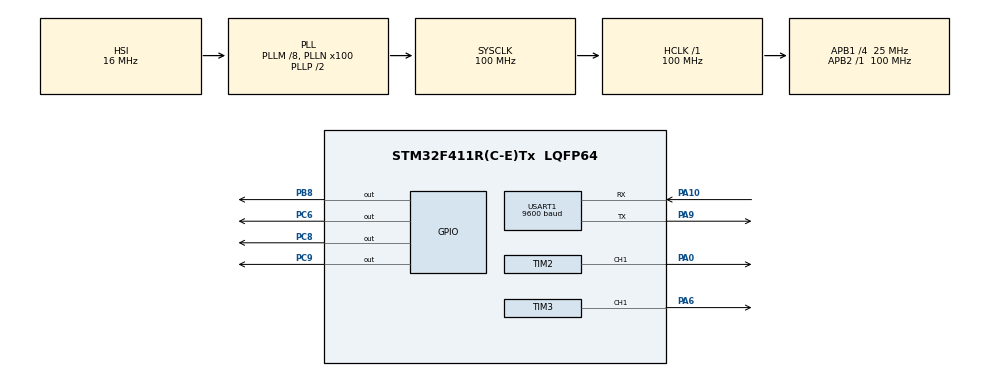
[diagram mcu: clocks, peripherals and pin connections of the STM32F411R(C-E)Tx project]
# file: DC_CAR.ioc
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Mcu.Family=STM32F4
Mcu.Name=STM32F411R(C-E)Tx
Mcu.Package=LQFP64
NVIC.PriorityGroup=NVIC_PRIORITYGROUP_4
NVIC.USART1_IRQn=true\:0\:0\:false\:false\:true\:true\:true\:true
PA0-WKUP.Signal=S_TIM2_CH1_ETR
PA10.Mode=Asynchronous
PA10.Signal=USART1_RX
PA13.Mode=Serial_Wire
PA13.Signal=SYS_JTMS-SWDIO
PA14.Mode=Serial_Wire
PA14.Signal=SYS_JTCK-SWCLK
PA6.Signal=S_TIM3_CH1
PA9.Mode=Asynchronous
PA9.Signal=USART1_TX
PB8.Signal=GPIO_Output
PC6.Signal=GPIO_Output
PC8.Signal=GPIO_Output
PC9.Signal=GPIO_Output
PH0\ -\ OSC_IN.Mode=HSE-External-Clock-Source
PH0\ -\ OSC_IN.Signal=RCC_OSC_IN
PH1\ -\ OSC_OUT.Mode=HSE-External-Clock-Source
PH1\ -\ OSC_OUT.Signal=RCC_OSC_OUT
ProjectManager.HeapSize=0x200
ProjectManager.StackSize=0x400
ProjectManager.TargetToolchain=STM32CubeIDE
RCC.48MHZClocksFreq_Value=50000000
RCC.AHBFreq_Value=100000000
RCC.APB1CLKDivider=RCC_HCLK_DIV4
RCC.APB1Freq_Value=25000000
RCC.APB1TimFreq_Value=50000000
RCC.APB2Freq_Value=100000000
RCC.APB2TimFreq_Value=100000000
RCC.CortexFreq_Value=100000000
RCC.HCLKFreq_Value=100000000
RCC.HSE_VALUE=8000000
RCC.HSI_VALUE=16000000
RCC.LSE_VALUE=32768
RCC.PLLM=8
RCC.PLLN=100
RCC.RCC_RTC_Clock_Source=RCC_RTCCLKSOURCE_LSI
RCC.RCC_RTC_Clock_SourceVirtual=RCC_RTCCLKSOURCE_LSI
RCC.SYSCLKFreq_VALUE=100000000
RCC.SYSCLKSource=RCC_SYSCLKSOURCE_PLLCLK
RCC.VCOOutputFreq_Value=200000000
SH.S_TIM2_CH1_ETR.0=TIM2_CH1,PWM Generation1 CH1
SH.S_TIM3_CH1.0=TIM3_CH1,PWM Generation1 CH1
TIM2.Channel-PWM\ Generation1\ CH1=TIM_CHANNEL_1
TIM3.Channel-PWM\ Generation1\ CH1=TIM_CHANNEL_1
TIM3.Period=2000-1
TIM3.Prescaler=1000-1
TIM3.Pulse-PWM\ Generation1\ CH1=300
USART1.BaudRate=9600
USART1.VirtualMode=VM_ASYNC
VP_TIM2_VS_ClockSourceINT.Mode=Internal
VP_TIM3_VS_ClockSourceINT.Mode=Internal
board=custom

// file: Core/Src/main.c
/* USER CODE BEGIN Header */
/**
  ******************************************************************************
  * @file           : main.c
  * @brief          : Main program body
  ******************************************************************************
  * @attention
  *
  * Copyright (c) 2026 STMicroelectronics.
  * All rights reserved.
  *
  * This software is licensed under terms that can be found in the LICENSE file
  * in the root directory of this software component.
  * If no LICENSE file comes with this software, it is provided AS-IS.
  *
  ******************************************************************************
  */
/* USER CODE END Header */
#include "main.h"
#include "tim.h"
#include "usart.h"
#include "gpio.h"

/* USER CODE BEGIN Includes */
#include <string.h>
#include "dc_car.h"
//#include "bt_slave.h"

/* USER CODE END Includes */

/* USER CODE BEGIN PV */

volatile uint8_t rxData[1];

/* USER CODE END PV */

void SystemClock_Config(void);
/* USER CODE BEGIN PFP */

void HAL_UART_RxCpltCallback(UART_HandleTypeDef *huart)		//블루투스 인터럽트
{
	uint8_t cmd = rxData[0];

     HAL_UART_Transmit(&huart1, &cmd, 1, 10);
     DC_CONTROL(cmd);

     HAL_UART_Receive_IT(&huart1, rxData, 1);

}

/* USER CODE END PFP */

int main(void)
{

  /* MCU Configuration--------------------------------------------------------*/

  /* Reset of all peripherals, Initializes the Flash interface and the Systick. */
  HAL_Init();

  /* Configure the system clock */
  SystemClock_Config();

  /* Initialize all configured peripherals */
  MX_GPIO_Init();
  MX_TIM3_Init();
  MX_TIM2_Init();
  MX_USART1_UART_Init();
  /* USER CODE BEGIN 2 */

//  BT_SlaveInit();
  HAL_TIM_Base_Start_IT(&htim3);
  HAL_TIM_Base_Start_IT(&htim2);
  HAL_UART_Receive_IT(&huart1, rxData, 1);  // 블루투스 수신 인터럽트 시작

//  GO_UP();

  /* USER CODE END 2 */

  /* Infinite loop */
  /* USER CODE BEGIN WHILE */
  while (1)
  {

//	  DC_CONTROL(rxData);

//	  DC_RUN();

    /* USER CODE END WHILE */

  }
}

void SystemClock_Config(void)
{
  RCC_OscInitTypeDef RCC_OscInitStruct = {0};
  RCC_ClkInitTypeDef RCC_ClkInitStruct = {0};

  /** Configure the main internal regulator output voltage
  */
  __HAL_RCC_PWR_CLK_ENABLE();
  __HAL_PWR_VOLTAGESCALING_CONFIG(PWR_REGULATOR_VOLTAGE_SCALE1);

  /** Initializes the RCC Oscillators according to the specified parameters
  * in the RCC_OscInitTypeDef structure.
  */
  RCC_OscInitStruct.OscillatorType = RCC_OSCILLATORTYPE_HSI;
  RCC_OscInitStruct.HSIState = RCC_HSI_ON;
  RCC_OscInitStruct.HSICalibrationValue = RCC_HSICALIBRATION_DEFAULT;
  RCC_OscInitStruct.PLL.PLLState = RCC_PLL_ON;
  RCC_OscInitStruct.PLL.PLLSource = RCC_PLLSOURCE_HSI;
  RCC_OscInitStruct.PLL.PLLM = 8;
  RCC_OscInitStruct.PLL.PLLN = 100;
  RCC_OscInitStruct.PLL.PLLP = RCC_PLLP_DIV2;
  RCC_OscInitStruct.PLL.PLLQ = 4;
  if (HAL_RCC_OscConfig(&RCC_OscInitStruct) != HAL_OK)
  {
    Error_Handler();
  }

  /** Initializes the CPU, AHB and APB buses clocks
  */
  RCC_ClkInitStruct.ClockType = RCC_CLOCKTYPE_HCLK|RCC_CLOCKTYPE_SYSCLK
                              |RCC_CLOCKTYPE_PCLK1|RCC_CLOCKTYPE_PCLK2;
  RCC_ClkInitStruct.SYSCLKSource = RCC_SYSCLKSOURCE_PLLCLK;
  RCC_ClkInitStruct.AHBCLKDivider = RCC_SYSCLK_DIV1;
  RCC_ClkInitStruct.APB1CLKDivider = RCC_HCLK_DIV4;
  RCC_ClkInitStruct.APB2CLKDivider = RCC_HCLK_DIV1;

  if (HAL_RCC_ClockConfig(&RCC_ClkInitStruct, FLASH_LATENCY_3) != HAL_OK)
  {
    Error_Handler();
  }
}

void Error_Handler(void)
{
  __disable_irq();
  while (1)
  {
  }
}
